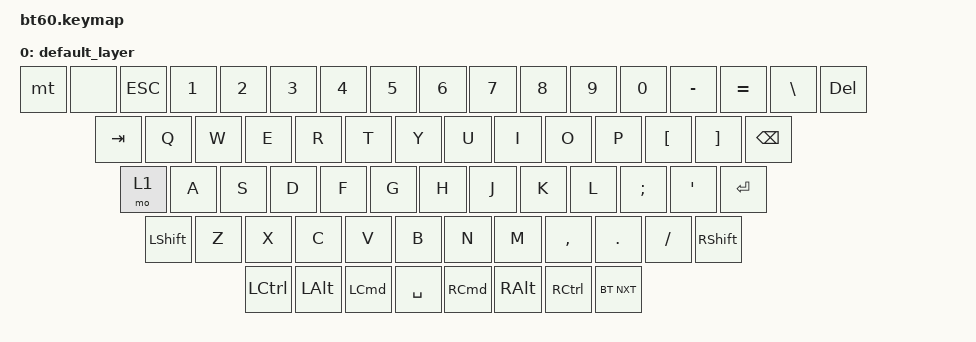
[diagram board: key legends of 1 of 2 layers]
#include <behaviors.dtsi>
#include <dt-bindings/zmk/keys.h>
#include <dt-bindings/zmk/bt.h>
#include <dt-bindings/zmk/rgb.h>
#include <dt-bindings/zmk/backlight.h>

/ {
	macros {
		umlautu: umlautu {
			label = "umlautu";
		 	compatible = "zmk,behavior-macro";
			#binding-cells = <0>;
			wait-ms = <1>;
			tap-ms = <1>;
			bindings
				= <&macro_press &kp RALT>
				, <&macro_tap &kp U>
				, <&macro_release &kp RALT>
				, <&macro_tap &kp U>
			;
		};
		umlauta: umlauta {
			label = "umlauta";
		 	compatible = "zmk,behavior-macro";
			#binding-cells = <0>;
			wait-ms = <1>;
			tap-ms = <1>;
			bindings
				= <&macro_press &kp RALT>
				, <&macro_tap &kp U>
				, <&macro_release &kp RALT>
				, <&macro_tap &kp A>
			;
		};
		umlauto: umlauto {
			label = "umlauto";
		 	compatible = "zmk,behavior-macro";
			#binding-cells = <0>;
			wait-ms = <1>;
			tap-ms = <1>;
			bindings
				= <&macro_press &kp RALT>
				, <&macro_tap &kp U>
				, <&macro_release &kp RALT>
				, <&macro_tap &kp O>
			;
		};
	};
	keymap {
		compatible = "zmk,keymap";
		default_layer {
				// ------------------------------------------------------------------------------------------
				// | ESC |  1  |  2  |  3  |  4  |  5  |  6  |  7  |  8  |  9  |  0  |  -  |  =  |   BKSP | DEL
				// | TAB  |  Q  |  W  |  E  |  R  |  T  |  Y  |  U  |  I  |  O  |  P  |  [  |  ]  |  \  |
				// | CAPS  |  A  |  S  |  D  |  F  |  G  |  H  |  J  |  K  |  L  |  ;  |  '  |    ENTER
				// | SHIFT  |  Z  |  X  |  C  |  V  |  B  |  N  |  M  |  ,  |  .  | /   |     SHIFT
				// | CTRL | ALT | CMD |            SPACE               | CMD | ALT |  CTRL |  BT_NXT
				// ------------------------------------------------------------------------------------------
			bindings = <
				&mt &none ESC &kp N1   &kp N2   &kp N3   &kp N4   &kp N5   &kp N6   &kp N7   &kp N8   &kp N9   &kp N0   &kp MINUS   &kp EQUAL   &kp BSLH &kp DEL
				&kp TAB   &kp Q   &kp W   &kp E   &kp R   &kp T   &kp Y   &kp U   &kp I   &kp O   &kp P   &kp LBKT   &kp RBKT   &kp BSPC
				&mo 1   &kp A   &kp S   &kp D   &kp F   &kp G   &kp H   &kp J   &kp K   &kp L   &kp SEMI   &kp SQT   &kp RET
				&kp LSHFT   &kp Z   &kp X   &kp C   &kp V   &kp B   &kp N   &kp M   &kp COMMA   &kp DOT   &kp FSLH   &kp RSHFT
				&kp LCTRL   &kp LEFT_ALT   &kp LCMD   &kp SPACE   &kp RCMD   &kp RALT   &kp RCTRL   &bt BT_NXT
			>;
			sensor-bindings = <&inc_dec_kp C_VOL_UP C_VOL_DN>;
		};
		raise {
				// ------------------------------------------------------------------------------------------
				// |  ~  | F1  | F2  | F3  | F4  | F5  | F6  | F7  | F8  | F9  | F10 | F11 | F12 |     |    
				// |     |     |     |     |     |     |     |  Ü  |     |  Ö  |     |     |     |    
				// |       |  Ä  | RGB_EFF | RGB_SPDD | RGB_SPDI |     | <- |  v  |  ^  | -> |     |     |    
				// |        | RGB_TOG | RGB_BRD | RGB_BRI | RGB_HUD | RGB_HUI | RGB_SAD | RGB_SAI |     |     |     |     
				// |      |     |     |                                |     | BT_CLR | RESET | BOOTLOADER 
				// ------------------------------------------------------------------------------------------
			bindings = <
				&kp GRAVE   &kp F1   &kp F2   &kp F3   &kp F4   &kp F5   &kp F6   &kp F7   &kp F8   &kp F9   &kp F10   &kp F11   &kp F12   &trans  &trans
				&trans   &trans   &trans   &trans   &trans   &trans   &trans   &umlautu  &trans   &umlauto   &trans   &trans   &trans   &kp DEL
				&trans   &umlauta   &rgb_ug RGB_EFF   &rgb_ug RGB_SPD   &rgb_ug RGB_SPI   &trans   &kp LEFT_ARROW   &kp DOWN_ARROW   &kp UP_ARROW   &kp RIGHT_ARROW   &trans   &trans   &trans
				&trans   &rgb_ug RGB_TOG   &rgb_ug RGB_BRD   &rgb_ug RGB_BRI   &rgb_ug RGB_HUD   &rgb_ug RGB_HUI   &rgb_ug RGB_SAD   &rgb_ug RGB_SAI   &trans   &trans   &trans   &trans
				&trans &trans   &trans   &trans   &trans   &bt BT_CLR   &sys_reset   &bootloader
			>;
			sensor-bindings = <&inc_dec_kp C_VOL_UP C_VOL_DN>;
		};
	};
};
